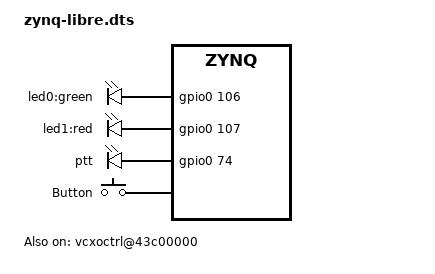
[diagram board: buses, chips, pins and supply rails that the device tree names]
// SPDX-License-Identifier: GPL-2.0
/*
 *
 * hdl_project: <Libre>
 * board_revision: <A>
 *
  */
/dts-v1/;
#include "zynq-libre.dtsi"



&adc0_ad9364 {
	/* This property is controlled by u-boot environment. */
	 adi,2rx-2tx-mode-enable;  
};

&cf_ad9364_dac_core_0 {
	/* This property is controlled by u-boot environment. */
	compatible = "adi,axi-ad9361-dds-6.00.a";
};


/ {
		
	leds {
		compatible = "gpio-leds";
		led0 {
			label = "led0:green";
			gpios = <&gpio0 106 0>;
			linux,default-trigger = "heartbeat";
		};
		led1 {
			label = "led1:red";
			gpios = <&gpio0 107 0>;
			linux,default-trigger = "heartbeat";
		};

		led2 {
			label = "ptt";
			gpios = <&gpio0 74 0>;
			default-state = "off";
		};
	};
    gpio_keys {
		compatible = "gpio-keys";
		#address-cells = <1>;
		#size-cells = <0>;

		button {
			interrupt-parent = <&gpio0>;
			interrupts = <12 IRQ_TYPE_EDGE_FALLING>;
			label = "Button";
			linux,code = <BTN_MISC>;
		};

	};

	amba_pl: amba_pl@0 {
        compatible = "simple-bus";
        #address-cells = <1>;
        #size-cells = <1>;
        ranges;

        // vcxoctrl is present
        vcxoctrl@43c00000 {
            compatible = "tezuka,antsdr";
            reg = <0x43c00000 0x1000>;
            status = "okay";

			tezuka,mode = "pps", "10mhz";
        };

       
    };
};
